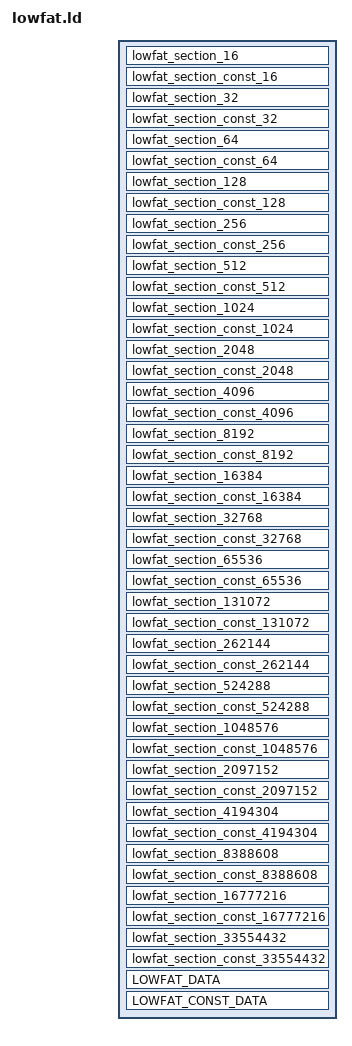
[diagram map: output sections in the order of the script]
/* AUTOMATICALLY GENERATED */

SECTIONS
{
	. = 0xbffff7000 + SIZEOF_HEADERS;
	lowfat_section_16 :
	{
		KEEP(*(lowfat_section_16))
	}
	ASSERT(. < 0xcffff7000, "Lowfat section (lowfat_section_16) is too big; max size is 2GB")
	. = 0xcffff7000 + SIZEOF_HEADERS;
	lowfat_section_const_16 :
	{
		KEEP(*(lowfat_section_const_16))
	}
	ASSERT(. < 0xdffff7000, "Lowfat section (lowfat_const_section_16) is too big; max size is 2GB")
	. = 0x13ffff7000 + SIZEOF_HEADERS;
	lowfat_section_32 :
	{
		KEEP(*(lowfat_section_32))
	}
	ASSERT(. < 0x14ffff7000, "Lowfat section (lowfat_section_32) is too big; max size is 2GB")
	. = 0x14ffff7000 + SIZEOF_HEADERS;
	lowfat_section_const_32 :
	{
		KEEP(*(lowfat_section_const_32))
	}
	ASSERT(. < 0x15ffff7000, "Lowfat section (lowfat_const_section_32) is too big; max size is 2GB")
	. = 0x23ffff7000 + SIZEOF_HEADERS;
	lowfat_section_64 :
	{
		KEEP(*(lowfat_section_64))
	}
	ASSERT(. < 0x24ffff7000, "Lowfat section (lowfat_section_64) is too big; max size is 2GB")
	. = 0x24ffff7000 + SIZEOF_HEADERS;
	lowfat_section_const_64 :
	{
		KEEP(*(lowfat_section_const_64))
	}
	ASSERT(. < 0x25ffff7000, "Lowfat section (lowfat_const_section_64) is too big; max size is 2GB")
	. = 0x43ffff7000 + SIZEOF_HEADERS;
	lowfat_section_128 :
	{
		KEEP(*(lowfat_section_128))
	}
	ASSERT(. < 0x44ffff7000, "Lowfat section (lowfat_section_128) is too big; max size is 2GB")
	. = 0x44ffff7000 + SIZEOF_HEADERS;
	lowfat_section_const_128 :
	{
		KEEP(*(lowfat_section_const_128))
	}
	ASSERT(. < 0x45ffff7000, "Lowfat section (lowfat_const_section_128) is too big; max size is 2GB")
	. = 0x6bffff7000 + SIZEOF_HEADERS;
	lowfat_section_256 :
	{
		KEEP(*(lowfat_section_256))
	}
	ASSERT(. < 0x6cffff7000, "Lowfat section (lowfat_section_256) is too big; max size is 2GB")
	. = 0x6cffff7000 + SIZEOF_HEADERS;
	lowfat_section_const_256 :
	{
		KEEP(*(lowfat_section_const_256))
	}
	ASSERT(. < 0x6dffff7000, "Lowfat section (lowfat_const_section_256) is too big; max size is 2GB")
	. = 0x93ffff7000 + SIZEOF_HEADERS;
	lowfat_section_512 :
	{
		KEEP(*(lowfat_section_512))
	}
	ASSERT(. < 0x94ffff7000, "Lowfat section (lowfat_section_512) is too big; max size is 2GB")
	. = 0x94ffff7000 + SIZEOF_HEADERS;
	lowfat_section_const_512 :
	{
		KEEP(*(lowfat_section_const_512))
	}
	ASSERT(. < 0x95ffff7000, "Lowfat section (lowfat_const_section_512) is too big; max size is 2GB")
	. = 0xbbffff7000 + SIZEOF_HEADERS;
	lowfat_section_1024 :
	{
		KEEP(*(lowfat_section_1024))
	}
	ASSERT(. < 0xbcffff7000, "Lowfat section (lowfat_section_1024) is too big; max size is 2GB")
	. = 0xbcffff7000 + SIZEOF_HEADERS;
	lowfat_section_const_1024 :
	{
		KEEP(*(lowfat_section_const_1024))
	}
	ASSERT(. < 0xbdffff7000, "Lowfat section (lowfat_const_section_1024) is too big; max size is 2GB")
	. = 0xe3ffff7000 + SIZEOF_HEADERS;
	lowfat_section_2048 :
	{
		KEEP(*(lowfat_section_2048))
	}
	ASSERT(. < 0xe4ffff7000, "Lowfat section (lowfat_section_2048) is too big; max size is 2GB")
	. = 0xe4ffff7000 + SIZEOF_HEADERS;
	lowfat_section_const_2048 :
	{
		KEEP(*(lowfat_section_const_2048))
	}
	ASSERT(. < 0xe5ffff7000, "Lowfat section (lowfat_const_section_2048) is too big; max size is 2GB")
	. = 0x10bffff7000 + SIZEOF_HEADERS;
	lowfat_section_4096 :
	{
		KEEP(*(lowfat_section_4096))
	}
	ASSERT(. < 0x10cffff7000, "Lowfat section (lowfat_section_4096) is too big; max size is 2GB")
	. = 0x10cffff7000 + SIZEOF_HEADERS;
	lowfat_section_const_4096 :
	{
		KEEP(*(lowfat_section_const_4096))
	}
	ASSERT(. < 0x10dffff7000, "Lowfat section (lowfat_const_section_4096) is too big; max size is 2GB")
	. = 0x133ffff7000 + SIZEOF_HEADERS;
	lowfat_section_8192 :
	{
		KEEP(*(lowfat_section_8192))
	}
	ASSERT(. < 0x134ffff7000, "Lowfat section (lowfat_section_8192) is too big; max size is 2GB")
	. = 0x134ffff7000 + SIZEOF_HEADERS;
	lowfat_section_const_8192 :
	{
		KEEP(*(lowfat_section_const_8192))
	}
	ASSERT(. < 0x135ffff7000, "Lowfat section (lowfat_const_section_8192) is too big; max size is 2GB")
	. = 0x153ffff7000 + SIZEOF_HEADERS;
	lowfat_section_16384 :
	{
		KEEP(*(lowfat_section_16384))
	}
	ASSERT(. < 0x154ffff7000, "Lowfat section (lowfat_section_16384) is too big; max size is 2GB")
	. = 0x154ffff7000 + SIZEOF_HEADERS;
	lowfat_section_const_16384 :
	{
		KEEP(*(lowfat_section_const_16384))
	}
	ASSERT(. < 0x155ffff7000, "Lowfat section (lowfat_const_section_16384) is too big; max size is 2GB")
	. = 0x15bffff7000 + SIZEOF_HEADERS;
	lowfat_section_32768 :
	{
		KEEP(*(lowfat_section_32768))
	}
	ASSERT(. < 0x15cffff7000, "Lowfat section (lowfat_section_32768) is too big; max size is 2GB")
	. = 0x15cffff7000 + SIZEOF_HEADERS;
	lowfat_section_const_32768 :
	{
		KEEP(*(lowfat_section_const_32768))
	}
	ASSERT(. < 0x15dffff7000, "Lowfat section (lowfat_const_section_32768) is too big; max size is 2GB")
	. = 0x163ffff7000 + SIZEOF_HEADERS;
	lowfat_section_65536 :
	{
		KEEP(*(lowfat_section_65536))
	}
	ASSERT(. < 0x164ffff7000, "Lowfat section (lowfat_section_65536) is too big; max size is 2GB")
	. = 0x164ffff7000 + SIZEOF_HEADERS;
	lowfat_section_const_65536 :
	{
		KEEP(*(lowfat_section_const_65536))
	}
	ASSERT(. < 0x165ffff7000, "Lowfat section (lowfat_const_section_65536) is too big; max size is 2GB")
	. = 0x16bffff7000 + SIZEOF_HEADERS;
	lowfat_section_131072 :
	{
		KEEP(*(lowfat_section_131072))
	}
	ASSERT(. < 0x16cffff7000, "Lowfat section (lowfat_section_131072) is too big; max size is 2GB")
	. = 0x16cffff7000 + SIZEOF_HEADERS;
	lowfat_section_const_131072 :
	{
		KEEP(*(lowfat_section_const_131072))
	}
	ASSERT(. < 0x16dffff7000, "Lowfat section (lowfat_const_section_131072) is too big; max size is 2GB")
	. = 0x173ffff7000 + SIZEOF_HEADERS;
	lowfat_section_262144 :
	{
		KEEP(*(lowfat_section_262144))
	}
	ASSERT(. < 0x174ffff7000, "Lowfat section (lowfat_section_262144) is too big; max size is 2GB")
	. = 0x174ffff7000 + SIZEOF_HEADERS;
	lowfat_section_const_262144 :
	{
		KEEP(*(lowfat_section_const_262144))
	}
	ASSERT(. < 0x175ffff7000, "Lowfat section (lowfat_const_section_262144) is too big; max size is 2GB")
	. = 0x17bffff7000 + SIZEOF_HEADERS;
	lowfat_section_524288 :
	{
		KEEP(*(lowfat_section_524288))
	}
	ASSERT(. < 0x17cffff7000, "Lowfat section (lowfat_section_524288) is too big; max size is 2GB")
	. = 0x17cffff7000 + SIZEOF_HEADERS;
	lowfat_section_const_524288 :
	{
		KEEP(*(lowfat_section_const_524288))
	}
	ASSERT(. < 0x17dffff7000, "Lowfat section (lowfat_const_section_524288) is too big; max size is 2GB")
	. = 0x183ffff7000 + SIZEOF_HEADERS;
	lowfat_section_1048576 :
	{
		KEEP(*(lowfat_section_1048576))
	}
	ASSERT(. < 0x184ffff7000, "Lowfat section (lowfat_section_1048576) is too big; max size is 2GB")
	. = 0x184ffff7000 + SIZEOF_HEADERS;
	lowfat_section_const_1048576 :
	{
		KEEP(*(lowfat_section_const_1048576))
	}
	ASSERT(. < 0x185ffff7000, "Lowfat section (lowfat_const_section_1048576) is too big; max size is 2GB")
	. = 0x18bffff7000 + SIZEOF_HEADERS;
	lowfat_section_2097152 :
	{
		KEEP(*(lowfat_section_2097152))
	}
	ASSERT(. < 0x18cffff7000, "Lowfat section (lowfat_section_2097152) is too big; max size is 2GB")
	. = 0x18cffff7000 + SIZEOF_HEADERS;
	lowfat_section_const_2097152 :
	{
		KEEP(*(lowfat_section_const_2097152))
	}
	ASSERT(. < 0x18dffff7000, "Lowfat section (lowfat_const_section_2097152) is too big; max size is 2GB")
	. = 0x193ffff7000 + SIZEOF_HEADERS;
	lowfat_section_4194304 :
	{
		KEEP(*(lowfat_section_4194304))
	}
	ASSERT(. < 0x194ffff7000, "Lowfat section (lowfat_section_4194304) is too big; max size is 2GB")
	. = 0x194ffff7000 + SIZEOF_HEADERS;
	lowfat_section_const_4194304 :
	{
		KEEP(*(lowfat_section_const_4194304))
	}
	ASSERT(. < 0x195ffff7000, "Lowfat section (lowfat_const_section_4194304) is too big; max size is 2GB")
	. = 0x19bffff7000 + SIZEOF_HEADERS;
	lowfat_section_8388608 :
	{
		KEEP(*(lowfat_section_8388608))
	}
	ASSERT(. < 0x19cffff7000, "Lowfat section (lowfat_section_8388608) is too big; max size is 2GB")
	. = 0x19cffff7000 + SIZEOF_HEADERS;
	lowfat_section_const_8388608 :
	{
		KEEP(*(lowfat_section_const_8388608))
	}
	ASSERT(. < 0x19dffff7000, "Lowfat section (lowfat_const_section_8388608) is too big; max size is 2GB")
	. = 0x1a3ffff7000 + SIZEOF_HEADERS;
	lowfat_section_16777216 :
	{
		KEEP(*(lowfat_section_16777216))
	}
	ASSERT(. < 0x1a4ffff7000, "Lowfat section (lowfat_section_16777216) is too big; max size is 2GB")
	. = 0x1a4ffff7000 + SIZEOF_HEADERS;
	lowfat_section_const_16777216 :
	{
		KEEP(*(lowfat_section_const_16777216))
	}
	ASSERT(. < 0x1a5ffff7000, "Lowfat section (lowfat_const_section_16777216) is too big; max size is 2GB")
	. = 0x1abffff7000 + SIZEOF_HEADERS;
	lowfat_section_33554432 :
	{
		KEEP(*(lowfat_section_33554432))
	}
	ASSERT(. < 0x1acffff7000, "Lowfat section (lowfat_section_33554432) is too big; max size is 2GB")
	. = 0x1acffff7000 + SIZEOF_HEADERS;
	lowfat_section_const_33554432 :
	{
		KEEP(*(lowfat_section_const_33554432))
	}
	ASSERT(. < 0x1adffff7000, "Lowfat section (lowfat_const_section_33554432) is too big; max size is 2GB")
	. = 0x2f000000000 + SIZEOF_HEADERS;
	LOWFAT_DATA :
	{
		KEEP(*(LOWFAT_DATA))
	}
	. = 0x2f800000000 + SIZEOF_HEADERS;
	LOWFAT_CONST_DATA :
	{
		KEEP(*(LOWFAT_CONST_DATA))
	}
}

INSERT AFTER .gnu.attributes;

